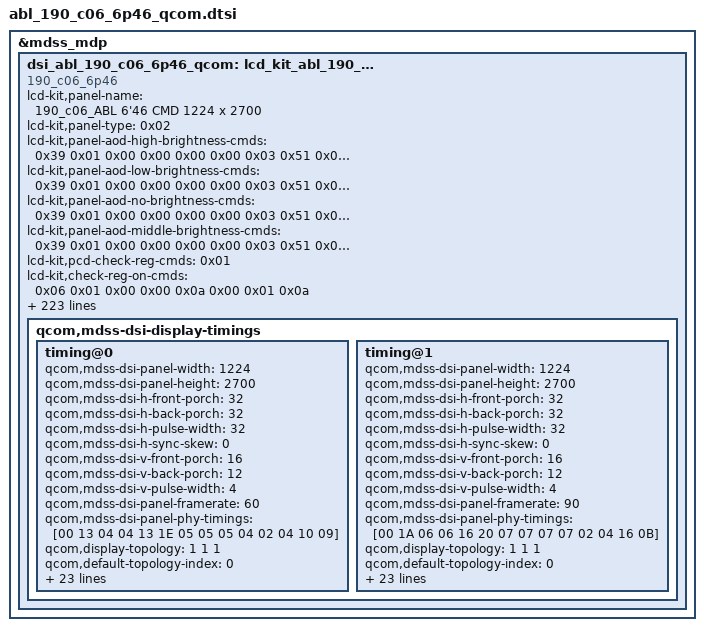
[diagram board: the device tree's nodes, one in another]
/* Copyright (c) 2013, The Linux Foundation. All rights reserved.
 *
 * This program is free software; you can redistribute it and/or modify
 * it under the terms of the GNU General Public License version 2 and
 * only version 2 as published by the Free Software Foundation.
 *
 * This program is distributed in the hope that it will be useful,
 * but WITHOUT ANY WARRANTY; without even the implied warranty of
 * MERCHANTABILITY or FITNESS FOR A PARTICULAR PURPOSE.  See the
 * GNU General Public License for more details.
 */

/*-------------------------------------------------------------------------
 * This file is autogenerated file using gcdb parser. Please do not edit it.
 * Update input XML file to add a new entry or update variable in this file
 * VERSION = 1.1
 *-----------------------------------------------------------------------*/
&mdss_mdp {
	dsi_abl_190_c06_6p46_qcom: lcd_kit_abl_190_c06_6p46_qcom {
		compatible = "190_c06_6p46";
		lcd-kit,panel-name = "190_c06_ABL 6'46 CMD 1224 x 2700";
		lcd-kit,panel-type = <0x02>;
		lcd-kit,panel-aod-high-brightness-cmds = <0x39 0x01 0x00 0x00 0x00 0x00 0x03 0x51 0x0F 0xFE>;
		lcd-kit,panel-aod-low-brightness-cmds = <0x39 0x01 0x00 0x00 0x00 0x00 0x03 0x51 0x01 0x64>;
		lcd-kit,panel-aod-no-brightness-cmds = <0x39 0x01 0x00 0x00 0x00 0x00 0x03 0x51 0x00 0x00>;
		lcd-kit,panel-aod-middle-brightness-cmds = <0x39 0x01 0x00 0x00 0x00 0x00 0x03 0x51 0x07 0x5F>;
		lcd-kit,pcd-check-reg-cmds = <0x01>;
		lcd-kit,check-reg-on-cmds = <0x06 0x01 0x00 0x00 0x0a 0x00 0x01 0x0a>;
		lcd-kit,check-reg-on-value = <0x9c>;
		lcd-kit,check-aod-reg-on-cmds = <0x06 0x01 0x00 0x00 0x0a 0x00 0x01 0x0a>;
		lcd-kit,check-aod-reg-on-value = <0xdc>;
		lcd-kit,check-reg-off-cmds = <0x06 0x01 0x00 0x00 0x0a 0x00 0x01 0x0a>;
		lcd-kit,check-reg-off-value = <0x08>;
		lcd-kit,check-reg-on-cmds-state = "dsi_lp_mode";
		lcd-kit,check-aod-reg-on-cmds-state = "dsi_lp_mode";
		lcd-kit,check-reg-off-cmds-state = "dsi_lp_mode";
		lcd-kit,pcd-check-reg-value = <0x01>;
		lcd-kit,pcd-errflag-check-support = <0>;
		lcd-kit,color-aod-detect-enter = <0x15 0x01 0x00 0x00 0x00 0x00 0x02 0xFE 0x00
			0x05 0x01 0x00 0x00 0x00 0x00 0x01 0x39
			0x39 0x01 0x00 0x00 0x00 0x00 0x03 0x51 0x0F 0xFE
			0x15 0x01 0x00 0x00 0x00 0x00 0x02 0xFE 0x00>;
		lcd-kit,color-aod-detect-enter-state = "dsi_lp_mode";
		lcd-kit,color-aod-detect-exit = <0x15 0x01 0x00 0x00 0x00 0x00 0x02 0xFE 0x00
			0x05 0x01 0x00 0x00 0x00 0x00 0x01 0x38
			0x15 0x01 0x00 0x00 0x00 0x00 0x02 0xFE 0x00>;
		lcd-kit,color-aod-detect-exit-state = "dsi_lp_mode";
		lcd-kit,hor-line-cmds = <0x15 0x01 0x00 0x00 0x00 0x00 0x02 0xFE 0x38
			0x15 0x01 0x00 0x00 0x00 0x00 0x02 0x18 0x13
			0x15 0x01 0x00 0x00 0x00 0x00 0x02 0xFE 0x00
			0x15 0x01 0x00 0x00 0x00 0x00 0x02 0xFA 0x01
			0x15 0x01 0x00 0x00 0x00 0x00 0x02 0xC2 0x08
			0x15 0x01 0x00 0x00 0x00 0x00 0x02 0x35 0x00
			0x39 0x01 0x00 0x00 0x00 0x00 0x03 0x51 0x0D 0xBB
			0x05 0x01 0x00 0x00 0x64 0x00 0x01 0x11
			0x05 0x01 0x00 0x00 0x00 0x00 0x01 0x29
			0x15 0x01 0x00 0x00 0x00 0x00 0x02 0xFE 0x40
			0x15 0x01 0x00 0x00 0x00 0x00 0x02 0xBD 0x00
			0x15 0x01 0x00 0x00 0x00 0x00 0x02 0xFE 0x00>;
		lcd-kit,hor-line-cmds-state = "dsi_lp_mode";
		lcd-kit,pcd-read-cmds = <0x15 0x01 0x00 0x00 0x00 0x00 0x02 0xFE 0x00
			0x05 0x01 0x00 0x00 0x00 0x00 0x01 0x28
			0x15 0x01 0x00 0x00 0x00 0x00 0x02 0xFE 0x40
			0x15 0x01 0x00 0x00 0x00 0x00 0x02 0x5D 0x28
			0x15 0x01 0x00 0x00 0x00 0x00 0x02 0x51 0x54
			0x06 0x01 0x00 0x00 0x00 0x00 0x01 0xDB
			0x15 0x01 0x00 0x00 0x00 0x00 0x02 0xFE 0x00
			0x05 0x01 0x00 0x00 0x00 0x00 0x01 0x29
			0x15 0x01 0x00 0x00 0x00 0x00 0x02 0xFE 0x40
			0x15 0x01 0x00 0x00 0x00 0x00 0x02 0x5D 0x08
			0x15 0x01 0x00 0x00 0x00 0x00 0x02 0xFE 0x00>;
		lcd-kit,pcd-read-cmds-state  = "dsi_lp_mode";
		lcd-kit,vtc-line-cmds = <0x15 0x01 0x00 0x00 0x00 0x00 0x02 0xFE 0x38
			0x15 0x01 0x00 0x00 0x00 0x00 0x02 0x18 0x13
			0x15 0x01 0x00 0x00 0x00 0x00 0x02 0xFE 0x00
			0x15 0x01 0x00 0x00 0x00 0x00 0x02 0xFA 0x01
			0x15 0x01 0x00 0x00 0x00 0x00 0x02 0xC2 0x08
			0x15 0x01 0x00 0x00 0x00 0x00 0x02 0x35 0x00
			0x39 0x01 0x00 0x00 0x00 0x00 0x03 0x51 0x0D 0xBB
			0x05 0x01 0x00 0x00 0x64 0x00 0x01 0x11
			0x05 0x01 0x00 0x00 0x00 0x00 0x01 0x29
			0x15 0x01 0x00 0x00 0x00 0x00 0x02 0xFE 0x40
			0x15 0x01 0x00 0x00 0x00 0x00 0x02 0xBD 0x00
			0x15 0x01 0x00 0x00 0x00 0x00 0x02 0xFE 0x00>;
		lcd-kit,vtc-line-cmds-state  = "dsi_lp_mode";
		lcd-kit,ddic-lv-det-enter1-cmds = <0x15 0x01 0x00 0x00 0x00 0x00 0x02 0xFE 0xB0
			0x15 0x01 0x00 0x00 0x00 0x00 0x02 0x16 0x23
			0x15 0x01 0x00 0x00 0x00 0x00 0x02 0xFE 0x00>;
		lcd-kit,ddic-lv-det-enter1-cmds-state  = "dsi_lp_mode";
		lcd-kit,ddic-lv-det-enter2-cmds = <0x15 0x01 0x00 0x00 0x00 0x00 0x02 0xFE 0xB0
			0x15 0x01 0x00 0x00 0x00 0x00 0x02 0x16 0x23
			0x15 0x01 0x00 0x00 0x00 0x00 0x02 0xFE 0x00>;
		lcd-kit,ddic-lv-det-enter2-cmds-state  = "dsi_lp_mode";
		lcd-kit,ddic-lv-det-enter3-cmds = <0x15 0x01 0x00 0x00 0x00 0x00 0x02 0xFE 0xB0
			0x15 0x01 0x00 0x00 0x00 0x00 0x02 0x16 0x23
			0x15 0x01 0x00 0x00 0x00 0x00 0x02 0xFE 0x00>;
		lcd-kit,ddic-lv-det-enter3-cmds-state  = "dsi_lp_mode";
		lcd-kit,ddic-lv-det-enter4-cmds = <0x15 0x01 0x00 0x00 0x00 0x00 0x02 0xFE 0xB0
			0x15 0x01 0x00 0x00 0x00 0x00 0x02 0x16 0x23
			0x15 0x01 0x00 0x00 0x00 0x00 0x02 0xFE 0x00>;
		lcd-kit,ddic-lv-det-enter4-cmds-state  = "dsi_lp_mode";
		lcd-kit,ddic-lv-det-rd1-cmds = <0x15 0x01 0x00 0x00 0x00 0x00 0x02 0xFE 0x00
			0x06 0x01 0x00 0x00 0x0a 0x00 0x01 0x0a
			0x15 0x01 0x00 0x00 0x00 0x00 0x02 0xFE 0x00>;
		lcd-kit,ddic-lv-det-rd1-cmds-state  = "dsi_lp_mode";
		lcd-kit,ddic-lv-det-rd2-cmds = <0x15 0x01 0x00 0x00 0x00 0x00 0x02 0xFE 0x00
			0x06 0x01 0x00 0x00 0x0a 0x00 0x01 0x0a
			0x15 0x01 0x00 0x00 0x00 0x00 0x02 0xFE 0x00>;
		lcd-kit,ddic-lv-det-rd2-cmds-state  = "dsi_lp_mode";
		lcd-kit,ddic-lv-det-rd3-cmds = <0x15 0x01 0x00 0x00 0x00 0x00 0x02 0xFE 0x00
			0x06 0x01 0x00 0x00 0x0a 0x00 0x01 0x0a
			0x15 0x01 0x00 0x00 0x00 0x00 0x02 0xFE 0x00>;
		lcd-kit,ddic-lv-det-rd3-cmds-state  = "dsi_lp_mode";
		lcd-kit,ddic-lv-det-rd4-cmds = <0x15 0x01 0x00 0x00 0x00 0x00 0x02 0xFE 0x00
			0x06 0x01 0x00 0x00 0x0a 0x00 0x01 0x0a
			0x15 0x01 0x00 0x00 0x00 0x00 0x02 0xFE 0x00>;
		lcd-kit,ddic-lv-det-rd4-cmds-state  = "dsi_lp_mode";
		lcd-kit,ddic-lv-det-value1 = <0x9c>;
		lcd-kit,ddic-lv-det-value2 = <0x9c>;
		lcd-kit,ddic-lv-det-value3 = <0x9c>;
		lcd-kit,ddic-lv-det-value4 = <0x9c>;
		lcd-kit,bl-after-frame = <0>;
		lcd-kit,cmd-async-support = <0>;
		lcd-kit,ap-aod-support = <1>;
		lcd-kit,mask-delay-time-before-fp = <16667>;
		lcd-kit,mask-delay-time-after-fp = <16667>;
		lcd-kit,left-time-to-te-us = <26667>;
		lcd-kit,right-time-to-te-us = <26917>;
		lcd-kit,te-interval-time-us = <16667>;
		lcd-kit,oneside-mode-support = <0>;
		lcd-kit,color-aod-detect-support = <1>;
		lcd-kit,elvdd-detect-support = <0>;
		lcd-kit,elvdd-detect-type = <2>;
		lcd-kit,elvdd-detect-value = <1>;
		lcd-kit,elvdd-delay = <50>;
		lcd-kit,elvdd-detect-gpio = <33>;
		lcd-kit,check-reg-on-support = <0>;
		lcd-kit,check-reg-on-support-dsm-report = <0>;
		lcd-kit,check-aod-reg-on-support = <0>;
		lcd-kit,check-aod-reg-on-support-dsm-report = <0>;
		lcd-kit,check-reg-off-support = <0>;
		lcd-kit,check-reg-off-support-dsm-report = <0>;
		lcd-kit,checksum-support = <0>;
		lcd-kit,pcd-cmds-support = <1>;
		lcd-kit,pcd-check-reg-value-compare-mode = <1>;
		lcd-kit,vtc-line-support = <1>;
		lcd-kit,ddic-lv-det-support = <0>;
		lcd-kit,hor-line-support = <1>;
		lcd-kit,hor-line-duration = <600>;
		lcd-kit,vtc-line-no-reset = <1>;
		qcom,mdss-dsi-panel-type = "dsi_cmd_mode";
		qcom,mdss-pan-physical-width-dimension = <69>;
		qcom,mdss-pan-physical-height-dimension = <154>;
		qcom,dsi-ctrl-num = <0>;
		qcom,dsi-phy-num = <0>;
		qcom,panel-supply-entries = <&dsi_panel_pwr_supply>;
		qcom,mdss-dsi-virtual-channel-id = <0>;
		qcom,mdss-dsi-h-sync-pulse = <0>;
		qcom,mdss-dsi-bllp-eof-power-mode;
		qcom,mdss-dsi-bllp-power-mode;
		qcom,mdss-dsi-dma-schedule-line = <1>;
		qcom,mdss-dsi-bpp = <24>;
		qcom,mdss-dsi-color-order = "rgb_swap_rgb";
		qcom,mdss-dsi-underflow-color = <0xff>;
		qcom,mdss-dsi-border-color = <0>;
		qcom,mdss-dsi-traffic-mode = "burst_mode";
		qcom,mdss-dsi-lane-map = "lane_map_0123";
		qcom,mdss-dsi-lane-0-state;
		qcom,mdss-dsi-lane-1-state;
		qcom,mdss-dsi-lane-2-state;
		qcom,mdss-dsi-lane-3-state;
		qcom,mdss-dsi-mdp-trigger = "none";
		qcom,mdss-dsi-dma-trigger = "trigger_sw";
		qcom,mdss-dsi-te-pin-select = <1>;
		qcom,mdss-dsi-wr-mem-start = <0x2c>;
		qcom,mdss-dsi-wr-mem-continue = <0x3c>;
		qcom,mdss-dsi-te-dcs-command = <1>;
		qcom,mdss-dsi-te-check-enable;
		qcom,mdss-dsi-te-using-te-pin;
		qcom,dsi-panel-gpio-address = <0x0F100000 0x1000>;
		qcom,dsi-panel-gpio-pins = <12 44 80>;
		qcom,dsi-panel-gpio-names = "reg-gpio", "reset-gpio", "platform-te-gpio";
		qcom,mdss-dsi-t-clk-post = <0>;
		qcom,mdss-dsi-t-clk-pre = <0>;
		qcom,dsi-select-clocks = "mux_byte_clk0", "mux_pixel_clk0";
		qcom,mdss-dsi-stream = <0>;
		lcd-kit,check-thread-support = <0>;
		lcd-kit,check-time-period = <5000>;
		lcd-kit,check-fold-support = <0>;
		lcd-kit,fold-low-power-support = <0>;
		lcd-kit,fold-height = <0>;
		lcd-kit,unfold-height = <0>;
		lcd-kit,power-support = <0>;
		lcd-kit,three-stage-poweron = <1>;
		qcom,apaod-lp2-need-sendcmd;
		lcd-kit,fold-lp-time = <0>;
		lcd-kit,fold-nolp-time = <0>;
		qcom,sublinks-count = <2>;
		qcom,lanes-per-sublink = <2>;
		qcom,mdss-dsi-panel-hdr-color-primaries = <14500 15500 32000 17000 15500 30000 8000 3000>;
		qcom,mdss-dsi-panel-peak-brightness = <4200000>;
		qcom,mdss-dsi-panel-blackness-level = <3230>;
		qcom,dynamic-mode-switch-enabled;
		qcom,dynamic-mode-switch-type = "dynamic-resolution-switch-immediate";
		qcom,mdss-dsi-bl-pmic-control-type = "bl_ctrl_dcs";
		qcom,mdss-dsi-bl-min-level = <1>;
		qcom,mdss-dsi-bl-max-level = <4095>;
		qcom,esd-check-enabled;
		qcom,mdss-dsi-panel-status-command = [15 01 00 00 00 00 02 FE 00
			06 01 00 00 00 00 01 0A
			06 01 00 00 00 00 01 0B
			06 01 00 00 00 00 01 0C
			06 01 00 00 00 00 01 0D
			15 01 00 00 00 00 02 FE 00];
		qcom,mdss-dsi-panel-status-command-state = "dsi_lp_mode";
		qcom,mdss-dsi-panel-status-check-mode = "reg_read";
		qcom,mdss-dsi-panel-status-read-length = <0 1 1 1 1 0>;
		qcom,mdss-dsi-panel-status-value = <0x9C>,<0x00>,<0x77>,<0x00>;
		lcd-kit,power-on-stage = <2 1 3
				9 1 3
				1 1 10>;
		lcd-kit,lp-on-stage = <5 1 2
				5 0 2
				5 1 32
				7 1 0
				6 1 0
				8 1 0>;
		lcd-kit,lp-off-stage = <0 0 0>;
		lcd-kit,power-off-stage = <7 0 0
				6 0 0
				8 0 0
				5 0 3
				1 0 3
				9 0 1
				2 0 5>;
		lcd-kit,only-power-off-stage = <0 0 0>;
		lcd-kit,pt-support = <1>;
		lcd-kit,panel-on-always-reset = <0>;
		lcd-kit,lcd-vci = <1 13 3000000 3000000 3000000 10000 80>;
		lcd-kit,lcd-iovcc = <1 12 1800000 1800000 1800000 60700 80>;
		lcd-kit,lcd-vdd = <1 16 1200000 1200000 1200000 30000 80>;
		lcd-kit,lcd-reset = <2 44 0>;
		lcd-kit,lcd-vci-name = "vdd";
		lcd-kit,lcd-iovcc-name = "vddio";
		lcd-kit,lcd-vdd-name = "ddic";
		lcd-kit,project-id-support = <0>;
		lcd-kit,default-project-id = "G240A7130";
		lcd-kit,sn-code-support = <1>;
		lcd-kit,oem-info-support = <1>;
		lcd-kit,oem-barcode-2d-support = <1>;
		lcd-kit,oem-barcode-2d-num-offset = <0>;
		lcd-kit,barcode-2d-cmds = <0x15 0x01 0x00 0x00 0x00 0x00 0x02 0xFE 0xC2
			0x06 0x01 0x00 0x00 0x00 0x00 0x01 0x00
			0x06 0x01 0x00 0x00 0x00 0x00 0x01 0x01
			0x06 0x01 0x00 0x00 0x00 0x00 0x01 0x02
			0x06 0x01 0x00 0x00 0x00 0x00 0x01 0x03
			0x06 0x01 0x00 0x00 0x00 0x00 0x01 0x04
			0x06 0x01 0x00 0x00 0x00 0x00 0x01 0x05
			0x06 0x01 0x00 0x00 0x00 0x00 0x01 0x06
			0x06 0x01 0x00 0x00 0x00 0x00 0x01 0x07
			0x06 0x01 0x00 0x00 0x00 0x00 0x01 0x08
			0x06 0x01 0x00 0x00 0x00 0x00 0x01 0x09
			0x06 0x01 0x00 0x00 0x00 0x00 0x01 0x0A
			0x06 0x01 0x00 0x00 0x00 0x00 0x01 0x0B
			0x06 0x01 0x00 0x00 0x00 0x00 0x01 0x0C
			0x06 0x01 0x00 0x00 0x00 0x00 0x01 0x0D
			0x06 0x01 0x00 0x00 0x00 0x00 0x01 0x0E
			0x06 0x01 0x00 0x00 0x00 0x00 0x01 0x0F
			0x06 0x01 0x00 0x00 0x00 0x00 0x01 0x10
			0x06 0x01 0x00 0x00 0x00 0x00 0x01 0x11
			0x06 0x01 0x00 0x00 0x00 0x00 0x01 0x12
			0x06 0x01 0x00 0x00 0x00 0x00 0x01 0x13
			0x06 0x01 0x00 0x00 0x00 0x00 0x01 0x14
			0x15 0x01 0x00 0x00 0x00 0x00 0x02 0xFE 0x00>;
		lcd-kit,barcode-2d-cmds-state = "dsi_lp_mode";
		lcd-kit,panel-getblmaxnit-type = <0>;
		lcd-kit,panel-blmaxnit-min-value = <400>;
		lcd-kit,inversion-support = <0>;
		lcd-kit,panel-gpio-offset = <336>;
		lcd-kit,finger-unlock-state-support = <0>;
		lcd-kit,esd-reg-te-check = <0>;
		lcd-kit,panel-bl-max-nit = <450>;
		lcd-kit,panel-bl-min = <3>;
		lcd-kit,panel-bl-max = <10000>;
		lcd-kit,panel-bl-def = <2074>;
		lcd-kit,check-reg-support = <0>;
		lcd-kit,thp-proximity-support = <0>;
		lcd-kit,proximity-reset-delay-min = <65>;
		lcd-kit,backlight-cmds = <0x39 0x01 0x00 0x00 0x00 0x00 0x03 0x51 0x00 0x00>;
		lcd-kit,backlight-cmds-state = "dsi_lp_mode";
		lcd-kit,backlight-order = <0>;
		lcd-kit,backlight-need-sync = <0>;
		lcd-kit,fps-support = <1>;
		lcd-kit,default-fps = <60>;
		lcd-kit,panel-support-fps-list = <60 90>;
		lcd-kit,fps-60-cmd = "vndservice call display.qservice 25 i32 0 i32 0";
		lcd-kit,fps-90-cmd = "vndservice call display.qservice 25 i32 1 i32 0";
		lcd-kit,fps-120-cmd = "";
		qcom,mdss-dsi-display-timings {
			timing@0 {
				qcom,mdss-dsi-panel-width = <1224>;
				qcom,mdss-dsi-panel-height = <2700>;
				qcom,mdss-dsi-h-front-porch = <32>;
				qcom,mdss-dsi-h-back-porch = <32>;
				qcom,mdss-dsi-h-pulse-width = <32>;
				qcom,mdss-dsi-h-sync-skew = <0>;
				qcom,mdss-dsi-v-front-porch = <16>;
				qcom,mdss-dsi-v-back-porch = <12>;
				qcom,mdss-dsi-v-pulse-width = <4>;
				qcom,mdss-dsi-panel-framerate = <60>;
				qcom,mdss-dsi-panel-phy-timings= [00 13 04 04 13 1E 05
			05 05 04 02 04 10 09];
				qcom,display-topology  = <1 1 1>;
				qcom,default-topology-index  = <0>;
				qcom,mdss-dsi-on-command = [15 01 00 00 00 00 02 FE 40
			15 01 00 00 00 00 02 84 12
			15 01 00 00 00 00 02 FE 62
			15 01 00 00 00 00 02 4E 00
			15 01 00 00 00 00 02 FE 40
			15 01 00 00 00 00 02 B6 02
			15 01 00 00 00 00 02 23 00
			15 01 00 00 00 00 02 24 54
			15 01 00 00 00 00 02 47 22
			15 01 00 00 00 00 02 48 13
			15 01 00 00 00 00 02 FE 38
			15 01 00 00 00 00 02 18 13
			15 01 00 00 00 00 02 FE 40
			15 01 00 00 00 00 02 68 01
			15 01 00 00 00 00 02 69 64
			15 01 00 00 00 00 02 FE 00
			15 01 00 00 00 00 02 FA 01
			15 01 00 00 00 00 02 C2 08
			15 01 00 00 00 00 02 35 00
			15 01 00 00 00 00 02 FE F4
			15 01 00 00 00 00 02 00 FF
			15 01 00 00 00 00 02 01 FF
			15 01 00 00 00 00 02 02 CF
			15 01 00 00 00 00 02 03 BC
			15 01 00 00 00 00 02 04 B9
			15 01 00 00 00 00 02 05 99
			15 01 00 00 00 00 02 06 02
			15 01 00 00 00 00 02 07 0A
			15 01 00 00 00 00 02 08 E0
			15 01 00 00 00 00 02 09 4C
			15 01 00 00 00 00 02 0A EB
			15 01 00 00 00 00 02 0B E8
			15 01 00 00 00 00 02 0C 32
			15 01 00 00 00 00 02 0D 07
			15 01 00 00 00 00 02 FE F4
			15 01 00 00 00 00 02 0D C0
			15 01 00 00 00 00 02 0E FF
			15 01 00 00 00 00 02 0F FF
			15 01 00 00 00 00 02 10 33
			15 01 00 00 00 00 02 11 6F
			15 01 00 00 00 00 02 12 6E
			15 01 00 00 00 00 02 13 A6
			15 01 00 00 00 00 02 14 80
			15 01 00 00 00 00 02 15 02
			15 01 00 00 00 00 02 16 38
			15 01 00 00 00 00 02 17 D3
			15 01 00 00 00 00 02 18 3A
			15 01 00 00 00 00 02 19 BA
			15 01 00 00 00 00 02 1A CC
			15 01 00 00 20 00 02 1B 01
			15 01 00 00 00 00 02 FE 38
			15 01 00 00 00 00 02 18 13
			15 01 00 00 00 00 02 FE D1
			15 01 00 00 00 00 02 D3 00
			15 01 00 00 00 00 02 D0 00
			15 01 00 00 00 00 02 D2 00
			15 01 00 00 00 00 02 D4 00
			15 01 00 00 00 00 02 B4 01
			15 01 00 00 00 00 02 FE F9
			15 01 00 00 00 00 02 00 AF
			15 01 00 00 00 00 02 1D 37
			15 01 00 00 00 00 02 FE 00
			39 01 00 00 00 00 03 51 00 00
			15 01 00 00 00 00 02 FE D4
			15 01 00 00 00 00 02 40 03
			15 01 00 00 00 00 02 FE FD
			15 01 00 00 00 00 02 80 F6
			15 01 00 00 00 00 02 FE A0
			15 01 00 00 00 00 02 06 36
			15 01 00 00 00 00 02 6E 07
			15 01 00 00 00 00 02 FE D0
			15 01 00 00 00 00 02 C4 10
			15 01 00 00 00 00 02 FE 00
			05 01 00 00 64 00 01 11
			05 01 00 00 00 00 01 29
			15 01 00 00 00 00 02 FE 40
			15 01 00 00 00 00 02 BD 00
			15 01 00 00 00 00 02 FE 00];
				qcom,mdss-dsi-on-command-state = "dsi_lp_mode";
				qcom,mdss-dsi-off-command = [15 01 00 00 00 00 02 FE 00
			05 01 00 00 23 00 01 28
			05 01 00 00 66 00 01 10];
				qcom,mdss-dsi-off-command-state = "dsi_lp_mode";
				qcom,compression-mode = "dsc";
				qcom,mdss-dsc-slice-height = <60>;
				qcom,mdss-dsc-slice-width = <1224>;
				qcom,mdss-dsc-slice-per-pkt = <1>;
				qcom,mdss-dsc-bit-per-component = <8>;
				qcom,mdss-dsc-bit-per-pixel = <8>;
				qcom,mdss-dsc-block-prediction-enable;
				qcom,mdss-dsi-timing-switch-command = [15 01 00 00 00 00 02 FE 40
			15 01 00 00 22 00 02 BD 00
			15 01 00 00 00 00 02 FE 00];
				qcom,mdss-dsi-timing-switch-command-state = "dsi_lp_mode";
				qcom,mdss-dsi-lp1-command = [15 01 00 00 00 00 02 FE 40
			15 01 00 00 00 00 02 BD 00
			15 01 00 00 00 00 02 FE 00
			05 01 00 00 00 00 01 39
			15 01 00 00 00 00 02 FE 00];
				qcom,mdss-dsi-lp1-command-state = "dsi_lp_mode";
				qcom,mdss-dsi-nolp-command = [15 01 00 00 00 00 02 FE 00
			39 01 00 00 00 00 03 51 00 00
			15 01 00 00 00 00 02 FE 40
			15 01 00 00 00 00 02 BD 00
			15 01 00 00 00 00 02 FE 00
			05 01 00 00 00 00 01 38
			15 01 00 00 00 00 02 FE 00];
				qcom,mdss-dsi-nolp-command-state = "dsi_lp_mode";
			};
			timing@1 {
				qcom,mdss-dsi-panel-width = <1224>;
				qcom,mdss-dsi-panel-height = <2700>;
				qcom,mdss-dsi-h-front-porch = <32>;
				qcom,mdss-dsi-h-back-porch = <32>;
				qcom,mdss-dsi-h-pulse-width = <32>;
				qcom,mdss-dsi-h-sync-skew = <0>;
				qcom,mdss-dsi-v-front-porch = <16>;
				qcom,mdss-dsi-v-back-porch = <12>;
				qcom,mdss-dsi-v-pulse-width = <4>;
				qcom,mdss-dsi-panel-framerate = <90>;
				qcom,mdss-dsi-panel-phy-timings= [00 1A 06 06 16 20 07
			07 07 07 02 04 16 0B];
				qcom,display-topology  = <1 1 1>;
				qcom,default-topology-index  = <0>;
				qcom,mdss-dsi-on-command = [15 01 00 00 00 00 02 FE 40
			15 01 00 00 00 00 02 84 12
			15 01 00 00 00 00 02 FE 62
			15 01 00 00 00 00 02 4E 00
			15 01 00 00 00 00 02 FE 40
			15 01 00 00 00 00 02 B6 02
			15 01 00 00 00 00 02 23 00
			15 01 00 00 00 00 02 24 54
			15 01 00 00 00 00 02 47 22
			15 01 00 00 00 00 02 48 13
			15 01 00 00 00 00 02 FE 38
			15 01 00 00 00 00 02 18 13
			15 01 00 00 00 00 02 FE 40
			15 01 00 00 00 00 02 68 01
			15 01 00 00 00 00 02 69 64
			15 01 00 00 00 00 02 FE 00
			15 01 00 00 00 00 02 FA 01
			15 01 00 00 00 00 02 C2 08
			15 01 00 00 00 00 02 35 00
			15 01 00 00 00 00 02 FE F4
			15 01 00 00 00 00 02 00 FF
			15 01 00 00 00 00 02 01 FF
			15 01 00 00 00 00 02 02 CF
			15 01 00 00 00 00 02 03 BC
			15 01 00 00 00 00 02 04 B9
			15 01 00 00 00 00 02 05 99
			15 01 00 00 00 00 02 06 02
			15 01 00 00 00 00 02 07 0A
			15 01 00 00 00 00 02 08 E0
			15 01 00 00 00 00 02 09 4C
			15 01 00 00 00 00 02 0A EB
			15 01 00 00 00 00 02 0B E8
			15 01 00 00 00 00 02 0C 32
			15 01 00 00 00 00 02 0D 07
			15 01 00 00 00 00 02 FE F4
			15 01 00 00 00 00 02 0D C0
			15 01 00 00 00 00 02 0E FF
			15 01 00 00 00 00 02 0F FF
			15 01 00 00 00 00 02 10 33
			15 01 00 00 00 00 02 11 6F
			15 01 00 00 00 00 02 12 6E
			15 01 00 00 00 00 02 13 A6
			15 01 00 00 00 00 02 14 80
			15 01 00 00 00 00 02 15 02
			15 01 00 00 00 00 02 16 38
			15 01 00 00 00 00 02 17 D3
			15 01 00 00 00 00 02 18 3A
			15 01 00 00 00 00 02 19 BA
			15 01 00 00 00 00 02 1A CC
			15 01 00 00 20 00 02 1B 01
			15 01 00 00 00 00 02 FE 38
			15 01 00 00 00 00 02 18 13
			15 01 00 00 00 00 02 FE D1
			15 01 00 00 00 00 02 D3 00
			15 01 00 00 00 00 02 D0 00
			15 01 00 00 00 00 02 D2 00
			15 01 00 00 00 00 02 D4 00
			15 01 00 00 00 00 02 B4 01
			15 01 00 00 00 00 02 FE F9
			15 01 00 00 00 00 02 00 AF
			15 01 00 00 00 00 02 1D 37
			15 01 00 00 00 00 02 FE 00
			39 01 00 00 00 00 03 51 00 00
			15 01 00 00 00 00 02 FE D4
			15 01 00 00 00 00 02 40 03
			15 01 00 00 00 00 02 FE FD
			15 01 00 00 00 00 02 80 F6
			15 01 00 00 00 00 02 FE A0
			15 01 00 00 00 00 02 06 36
			15 01 00 00 00 00 02 6E 07
			15 01 00 00 00 00 02 FE D0
			15 01 00 00 00 00 02 C4 10
			15 01 00 00 00 00 02 FE 00
			05 01 00 00 64 00 01 11
			05 01 00 00 00 00 01 29
			15 01 00 00 00 00 02 FE 40
			15 01 00 00 00 00 02 BD 05
			15 01 00 00 00 00 02 FE 00];
				qcom,mdss-dsi-on-command-state = "dsi_lp_mode";
				qcom,mdss-dsi-off-command = [15 01 00 00 00 00 02 FE 00
			05 01 00 00 23 00 01 28
			05 01 00 00 66 00 01 10];
				qcom,mdss-dsi-off-command-state = "dsi_lp_mode";
				qcom,compression-mode = "dsc";
				qcom,mdss-dsc-slice-height = <60>;
				qcom,mdss-dsc-slice-width = <1224>;
				qcom,mdss-dsc-slice-per-pkt = <1>;
				qcom,mdss-dsc-bit-per-component = <8>;
				qcom,mdss-dsc-bit-per-pixel = <8>;
				qcom,mdss-dsc-block-prediction-enable;
				qcom,mdss-dsi-timing-switch-command = [15 01 00 00 00 00 02 FE 40
			15 01 00 00 00 00 02 BD 05
			15 01 00 00 00 00 02 FE 00];
				qcom,mdss-dsi-timing-switch-command-state = "dsi_lp_mode";
				qcom,mdss-dsi-lp1-command = [15 01 00 00 00 00 02 FE 40
			15 01 00 00 00 00 02 BD 00
			15 01 00 00 00 00 02 FE 00
			05 01 00 00 00 00 01 39
			15 01 00 00 00 00 02 FE 00];
				qcom,mdss-dsi-lp1-command-state = "dsi_lp_mode";
				qcom,mdss-dsi-nolp-command = [15 01 00 00 00 00 02 FE 00
			39 01 00 00 00 00 03 51 00 00
			15 01 00 00 00 00 02 FE 40
			15 01 00 00 00 00 02 BD 05
			15 01 00 00 00 00 02 FE 00
			05 01 00 00 00 00 01 38
			15 01 00 00 00 00 02 FE 00];
				qcom,mdss-dsi-nolp-command-state = "dsi_lp_mode";
			};
		};
    };
};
